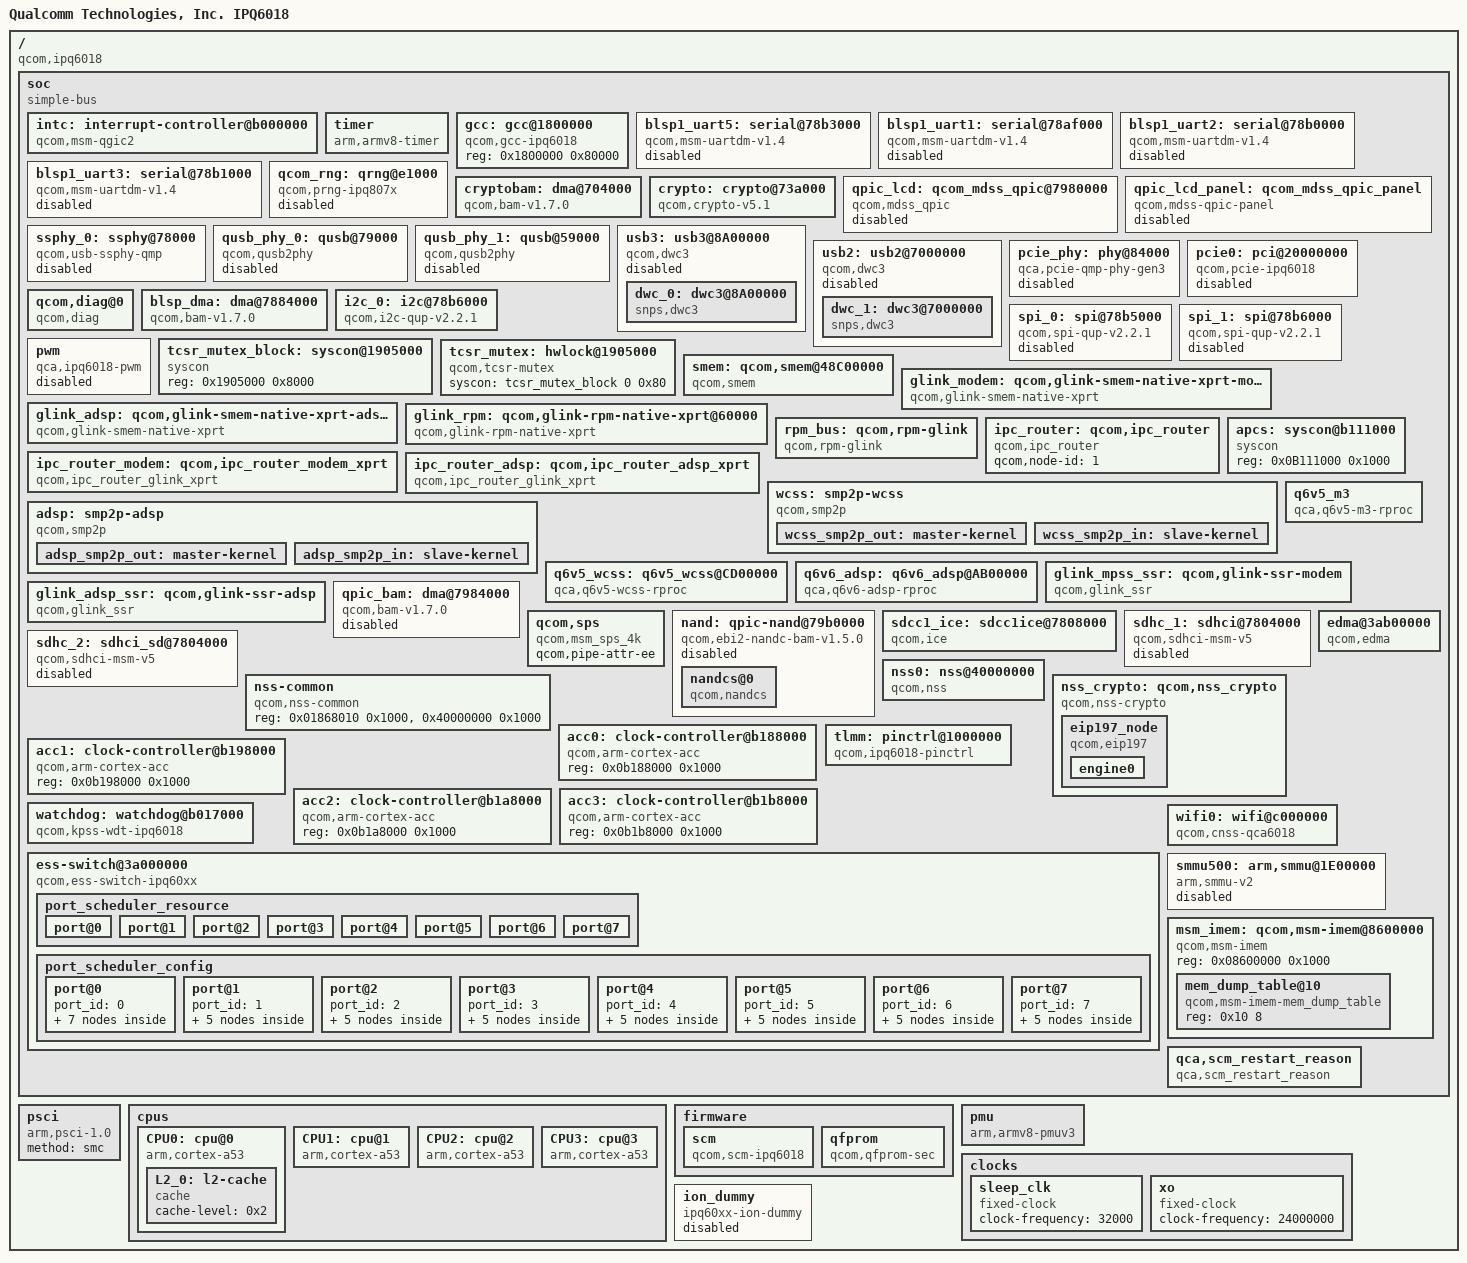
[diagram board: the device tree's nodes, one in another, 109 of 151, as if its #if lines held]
/*
 * Copyright (c) 2018-2019, The Linux Foundation. All rights reserved.
 *
 * Permission to use, copy, modify, and/or distribute this software for any
 * purpose with or without fee is hereby granted, provided that the above
 * copyright notice and this permission notice appear in all copies.
 *
 * THE SOFTWARE IS PROVIDED "AS IS" AND THE AUTHOR DISCLAIMS ALL WARRANTIES
 * WITH REGARD TO THIS SOFTWARE INCLUDING ALL IMPLIED WARRANTIES OF
 * MERCHANTABILITY AND FITNESS. IN NO EVENT SHALL THE AUTHOR BE LIABLE FOR
 * ANY SPECIAL, DIRECT, INDIRECT, OR CONSEQUENTIAL DAMAGES OR ANY DAMAGES
 * WHATSOEVER RESULTING FROM LOSS OF USE, DATA OR PROFITS, WHETHER IN AN
 * ACTION OF CONTRACT, NEGLIGENCE OR OTHER TORTIOUS ACTION, ARISING OUT OF
 * OR IN CONNECTION WITH THE USE OR PERFORMANCE OF THIS SOFTWARE.
 */

#include <dt-bindings/interrupt-controller/arm-gic.h>
#include <dt-bindings/clock/qcom,gcc-ipq6018.h>
#include "qcom-ipq6018-memory.dtsi"

/ {
	model = "Qualcomm Technologies, Inc. IPQ6018";
	compatible = "qcom,ipq6018";
	qcom,msm-id = <0x192 0x0>;

	soc: soc {
		#address-cells = <0x1>;
		#size-cells = <0x1>;
		ranges = <0 0 0 0xffffffff>;
		compatible = "simple-bus";

		intc: interrupt-controller@b000000 {
			compatible = "qcom,msm-qgic2";
			interrupt-controller;
			#interrupt-cells = <0x3>;
			reg = <0xb000000 0x1000>, <0xb002000 0x1000>;
		};

		timer {
			compatible = "arm,armv8-timer";
			interrupts = <GIC_PPI 2 (GIC_CPU_MASK_SIMPLE(4) | IRQ_TYPE_LEVEL_LOW)>,
				     <GIC_PPI 3 (GIC_CPU_MASK_SIMPLE(4) | IRQ_TYPE_LEVEL_LOW)>,
				     <GIC_PPI 4 (GIC_CPU_MASK_SIMPLE(4) | IRQ_TYPE_LEVEL_LOW)>,
				     <GIC_PPI 1 (GIC_CPU_MASK_SIMPLE(4) | IRQ_TYPE_LEVEL_LOW)>;
		};

		gcc: gcc@1800000 {
			compatible = "qcom,gcc-ipq6018";
			reg = <0x1800000 0x80000>;
			#clock-cells = <0x1>;
			#reset-cells = <0x1>;
		};

		blsp1_uart5: serial@78b3000 {
			compatible = "qcom,msm-uartdm-v1.4", "qcom,msm-uartdm";
			reg = <0x78b3000 0x200>;
			interrupts = <GIC_SPI 308 IRQ_TYPE_LEVEL_HIGH>;
			clocks = <&gcc GCC_BLSP1_UART5_APPS_CLK>,
				 <&gcc GCC_BLSP1_AHB_CLK>;
			clock-names = "core", "iface";
			status = "disabled";
		};

		blsp1_uart1: serial@78af000 {
			compatible = "qcom,msm-uartdm-v1.4", "qcom,msm-uartdm";
			reg = <0x78af000 0x200>;
			interrupts = <GIC_SPI 107 IRQ_TYPE_LEVEL_HIGH>;
			clocks = <&gcc GCC_BLSP1_UART1_APPS_CLK>,
				 <&gcc GCC_BLSP1_AHB_CLK>;
			clock-names = "core", "iface";
			status = "disabled";
		};

		blsp1_uart2: serial@78b0000 {
			compatible = "qcom,msm-uartdm-v1.4", "qcom,msm-uartdm";
			reg = <0x78b0000 0x200>;
			interrupts = <GIC_SPI 108 IRQ_TYPE_LEVEL_HIGH>;
			clocks = <&gcc GCC_BLSP1_UART2_APPS_CLK>,
				<&gcc GCC_BLSP1_AHB_CLK>;
			clock-names = "core", "iface";
			status = "disabled";
		};

		blsp1_uart3: serial@78b1000 {
			compatible = "qcom,msm-uartdm-v1.4", "qcom,msm-uartdm";
			reg = <0x78b1000 0x200>;
			interrupts = <GIC_SPI 306 IRQ_TYPE_LEVEL_HIGH>;
			clocks = <&gcc GCC_BLSP1_UART3_APPS_CLK>,
				<&gcc GCC_BLSP1_AHB_CLK>;
			clock-names = "core", "iface";
			status = "disabled";
		};

		qcom_rng: qrng@e1000 {
			compatible = "qcom,prng-ipq807x";
			reg = <0xe3000 0x1000>;
			clocks = <&gcc GCC_PRNG_AHB_CLK>;
			clock-names = "core";
			status = "disabled";
		};

		cryptobam: dma@704000 {
			compatible = "qcom,bam-v1.7.0";
			reg = <0x00704000 0x20000>;
			interrupts = <GIC_SPI 207 IRQ_TYPE_NONE>;
			clocks = <&gcc GCC_CRYPTO_AHB_CLK>;
			clock-names = "bam_clk";
			#dma-cells = <1>;
			qcom,ee = <1>;
			qcom,controlled-remotely = <1>;
			qcom,config-pipe-trust-reg = <0>;
		};

		crypto: crypto@73a000 {
			compatible = "qcom,crypto-v5.1";
			reg = <0x0073a000 0x6000>;
			clocks = <&gcc GCC_CRYPTO_AHB_CLK>,
				<&gcc GCC_CRYPTO_AXI_CLK>,
				<&gcc GCC_CRYPTO_CLK>;
			clock-names = "iface", "bus", "core";
			dmas = <&cryptobam 2>, <&cryptobam 3>;
			dma-names = "rx", "tx";
		};

		qpic_lcd: qcom_mdss_qpic@7980000 {
			compatible = "qcom,mdss_qpic";
			reg = <0x7980000 0x24000>;
			interrupts = <GIC_SPI 151 IRQ_TYPE_NONE>;
			clocks = <&gcc GCC_QPIC_CLK>,
				<&gcc GCC_QPIC_AHB_CLK>;
			clock-names = "core", "aon";
			dmas = <&qpic_bam 6>;
			dma-names = "chan";
			status = "disabled";
		};

		qpic_lcd_panel: qcom_mdss_qpic_panel {
			compatible = "qcom,mdss-qpic-panel";
			label = "qpic lcd panel";
			qcom,mdss-pan-res = <800 480>;
			qcom,mdss-pan-bpp = <18>;
			qcom,refresh_rate = <60>;
			status = "disabled";
		};

		ssphy_0: ssphy@78000 {
			compatible = "qcom,usb-ssphy-qmp";
			reg = <0x78000 0x45c>,
				<0x0193f244 0x4>,
				<0x08af8800 0x100>,
				<0x7e000 0x18>;
			reg-names = "qmp_phy_base",
				    "vls_clamp_reg",
				    "qscratch_base",
				    "ahb2phy_base";
			qcom,qmp-phy-init-seq = <0xac 0x14 0x1a 0x00
						0x34 0x08 0x08 0x00
						0x174 0x30 0x30 0x00
						0x3c 0x06 0x06 0x00
						0xb4 0x00 0x00 0x00
						0xb8 0x08 0x08 0x00
						0x194 0x06 0x06 0x3e8
						0x19c 0x01 0x01 0x00
						0x178 0x00 0x00 0x00
						0xd0 0x68 0x68 0x00
						0xdc 0xab 0xab 0x00
						0xe0 0xaa 0xaa 0x00
						0xe4 0x02 0x02 0x00
						0x78 0x09 0x09 0x00
						0x84 0x16 0x16 0x00
						0x90 0x28 0x28 0x00
						0x108 0xa0 0xa0 0x00
						0x10c 0x00 0x00 0x00
						0x184 0x0a 0x0a 0x00
						0x4c 0xaa 0xaa 0x00
						0x50 0x29 0x29 0x00
						0x54 0x00 0x00 0x00
						0xc8 0x00 0x00 0x00
						0x18c 0x00 0x00 0x00
						0xcc 0x00 0x00 0x00
						0x128 0x00 0x00 0x00
						0x0c 0x0a 0x0a 0x00
						0x10 0x01 0x01 0x00
						0x1c 0x7d 0x7d 0x00
						0x20 0x01 0x01 0x00
						0x14 0x00 0x00 0x00
						0x18 0x00 0x00 0x00
						0x24 0x0a 0x0a 0x00
						0x28 0x05 0x05 0x00
						0x48 0x0f 0x0f 0x00
						0x70 0x0f 0x0f 0x00
						0x100 0x80 0x80 0x00
						0x440 0x0b 0x0b 0x00
						0x4d8 0x02 0x02 0x00
						0x4dc 0x6c 0x6c 0x00
						0x4e0 0xbb 0xb8 0x00
						0x508 0x77 0x77 0x00
						0x50c 0x80 0x80 0x00
						0x514 0x03 0x03 0x00
						0x51c 0x16 0x16 0x00
						0x448 0x75 0x75 0x00
						0x454 0x00 0x00 0x00
						0x40c 0x0a 0x0a 0x00
						0x41c 0x06 0x06 0x00
						0x510 0x00 0x00 0x00
						0x268 0x45 0x45 0x00
						0x2ac 0x12 0x12 0x00
						0x294 0x06 0x06 0x00
						0x254 0x00 0x00 0x00
						0x8c8 0x83 0x83 0x00
						0x8c4 0x02 0x02 0x00
						0x8cc 0x09 0x09 0x00
						0x8d0 0xa2 0xa2 0x00
						0x8d4 0x85 0x85 0x00
						0x880 0xd1 0xd1 0x00
						0x884 0x1f 0x1f 0x00
						0x888 0x47 0x47 0x00
						0x80c 0x9f 0x9f 0x00
						0x824 0x17 0x17 0x00
						0x828 0x0f 0x0f 0x00
						0x8b8 0x75 0x75 0x00
						0x8bc 0x13 0x13 0x00
						0x8b0 0x86 0x86 0x00
						0x8a0 0x04 0x04 0x00
						0x88c 0x44 0x44 0x00
						0x870 0xe7 0xe7 0x00
						0x874 0x03 0x03 0x00
						0x878 0x40 0x40 0x00
						0x87c 0x00 0x00 0x00
						0x9d8 0x88 0x88 0x00
						0xffffffff 0xffffffff 0x00 0x00>;
			qcom,qmp-phy-reg-offset = <0x988 0x98c 0x990 0x994
						0x974 0x8d8 0x8dc 0x804 0x800
						0x808>;

			clocks = <&gcc GCC_USB0_AUX_CLK>,
				 <&gcc GCC_USB0_PIPE_CLK>;

			clock-names = "aux_clk", "pipe_clk";

			resets =  <&gcc GCC_USB0_PHY_BCR>,
				  <&gcc GCC_USB3PHY_0_PHY_BCR>;
			reset-names = "usb3_phy_reset",
				      "usb3phy_phy_reset";

			status = "disabled";
		 };

		qusb_phy_0: qusb@79000 {
			compatible = "qcom,qusb2phy";
			reg = <0x079000 0x180>,
			      <0x08af8800 0x400>,
			      <0x01841030 0x4>,
			      <0x08A0C12C 0x4>;
			reg-names = "qusb_phy_base",
				    "qscratch_base",
				    "ref_clk_addr",
				    "usb3_guctl_addr";

			qcom,qusb-phy-init-seq = <0x14 0x00
						  0xF8 0x80
						  0xB3 0x84
						  0x83 0x88
						  0xC0 0x8C
						  0x30 0x08
						  0x79 0x0C
						  0x21 0x10
						  0x00 0x90
						  0x00 0x18
						  0x14 0x9C
						  0x80 0x04
						  0x9F 0x1C>;
			phy_type= "utmi";

			resets = <&gcc GCC_QUSB2_0_PHY_BCR>;
			reset-names = "usb2_phy_reset";

			status = "disabled";
		};

		qusb_phy_1: qusb@59000 {
			compatible = "qcom,qusb2phy";
			reg = <0x059000 0x180>,
			      <0x070f8800 0x400>,
			      <0x01841030 0x4>,
			      <0x0700C12C 0x4>;
			reg-names = "qusb_phy_base",
				    "qscratch_base",
				    "ref_clk_addr",
				    "usb3_guctl_addr";
			qcom,qusb-phy-init-seq = <0x14 0x00
						  0xF8 0x80
						  0xB3 0x84
						  0x83 0x88
						  0xC0 0x8C
						  0x30 0x08
						  0x79 0x0C
						  0x21 0x10
						  0x00 0x90
						  0x00 0x18
						  0x14 0x9C
						  0x80 0x04
						  0x9F 0x1C>;

			phy_type= "utmi";

			resets = <&gcc GCC_QUSB2_1_PHY_BCR>;
			reset-names = "usb2_phy_reset";

			status = "disabled";
		};

		usb3: usb3@8A00000 {
			compatible = "qcom,dwc3";
			#address-cells = <1>;
			#size-cells = <1>;
			ranges;
			reg = <0x8AF8800 0x100>;
			reg-names = "qscratch_base";
			clocks = <&gcc GCC_SNOC_BUS_TIMEOUT2_AHB_CLK>,
			         <&gcc GCC_SYS_NOC_USB0_AXI_CLK>,
			         <&gcc GCC_USB0_MASTER_CLK>,
			         <&gcc GCC_USB0_SLEEP_CLK>,
			         <&gcc GCC_USB0_MOCK_UTMI_CLK>,
			         <&gcc GCC_USB0_PHY_CFG_AHB_CLK>,
			         <&gcc GCC_USB0_AUX_CLK>,
			         <&gcc GCC_USB0_PIPE_CLK>;
			clock-names = "snoc_bus_timeout2",
				      "sys_noc_axi",
				      "master",
				      "sleep",
				      "mock_utmi",
				      "cfg_ahb_clk",
				      "aux_clk",
				      "pipe_clk";
			assigned-clocks = <&gcc GCC_SYS_NOC_USB0_AXI_CLK>,
					  <&gcc GCC_USB0_MASTER_CLK>,
					  <&gcc GCC_USB0_MOCK_UTMI_CLK>;
			assigned-clock-rates = <133330000>,
						<133330000>,
						<20000000>;
			qca,host = <1>;
			status = "disabled";

			dwc_0: dwc3@8A00000 {
			       compatible = "snps,dwc3";
			       reg = <0x8A00000 0xcd00>;
			       interrupts = <GIC_SPI 140 IRQ_TYPE_NONE>;
			       usb-phy = <&qusb_phy_0>, <&ssphy_0>;
			       tx-fifo-resize;
			       snps,usb3-u1u2-disable;
			       snps,nominal-elastic-buffer;
			       snps,is-utmi-l1-suspend;
			       snps,hird-threshold = /bits/ 8 <0x0>;
			       snps,dis_u2_susphy_quirk;
			       snps,dis_u3_susphy_quirk;
			       usb2-susphy-quirk;
			       qcom,emulation = <1>;
			       dr_mode = "host";
			};
		};

		usb2: usb2@7000000 {
			compatible = "qcom,dwc3";
			#address-cells = <1>;
			#size-cells = <1>;
			ranges;
			reg = <0x70F8800 0x100>;
			reg-names = "qscratch_base";
			clocks = <&gcc GCC_USB1_MASTER_CLK>,
			         <&gcc GCC_USB1_SLEEP_CLK>,
			         <&gcc GCC_USB1_MOCK_UTMI_CLK>,
			         <&gcc GCC_USB1_PHY_CFG_AHB_CLK>;
			clock-names = "master",
				      "sleep",
				      "mock_utmi",
				      "cfg_ahb_clk";

			assigned-clocks = <&gcc GCC_USB1_MASTER_CLK>,
					  <&gcc GCC_USB1_MOCK_UTMI_CLK>;
			assigned-clock-rates = <133330000>,
					       <20000000>;
			qca,host = <1>;
			status = "disabled";

			dwc_1: dwc3@7000000 {
			       compatible = "snps,dwc3";
			       reg = <0x7000000 0xcd00>;
			       interrupts = <GIC_SPI 99 IRQ_TYPE_NONE>;
			       usb-phy = <&qusb_phy_1>;
			       tx-fifo-resize;
			       snps,usb3-u1u2-disable;
			       snps,nominal-elastic-buffer;
			       snps,is-utmi-l1-suspend;
			       snps,hird-threshold = /bits/ 8 <0x0>;
			       snps,dis_u2_susphy_quirk;
			       snps,dis_u3_susphy_quirk;
			       usb2-susphy-quirk;
			       qcom,emulation = <1>;
			       dr_mode = "host";
			};
		};

		pcie_phy: phy@84000 {
			compatible = "qca,pcie-qmp-phy-gen3";
			reg = <0x84000 0x1000>;
			qcom,qmp-pcie-phy-init-seq = <0x840 0x01 /*PCS_COM_POWER_DOWN_CONTROL */
						      0x03C 0x18 /* PCIE_0_QSERDES_PLL_BIAS_EN_CLKBUFLR_EN */
						      0x0A4 0x01 /* PCIE_0_QSERDES_PLL_BIAS_EN_CTRL_BY_PSM */
						      0x16C 0x31 /* PCIE_0_QSERDES_PLL_CLK_SELECT */
						      0x050 0x0F /* PCIE_0_QSERDES_PLL_PLL_IVCO */
						      0x074 0x0F /* PCIE_0_QSERDES_PLL_BG_TRIM */
						      0xFFFFFFFF 0x01 /* 1ms delay */
						      0x18C 0x06 /* PCIE_0_QSERDES_PLL_CMN_CONFIG */
						      0x0C4 0x42 /* PCIE_0_QSERDES_PLL_LOCK_CMP_EN */
						      0x0B0 0x20 /* PCIE_0_QSERDES_PLL_RESETSM_CNTRL */
						      0x194 0x01 /* PCIE_0_QSERDES_PLL_SVS_MODE_CLK_SEL */
						      0x120 0x04 /* PCIE_0_QSERDES_PLL_VCO_TUNE_MAP */
						      0x194 0x05 /* PCIE_0_QSERDES_PLL_SVS_MODE_CLK_SEL */
						      0x13C 0xFF /* PCIE_0_QSERDES_PLL_VCO_TUNE_TIMER1 */
						      0x140 0x3F /* PCIE_0_QSERDES_PLL_VCO_TUNE_TIMER2 */
						      0x184 0x30 /* PCIE_0_QSERDES_PLL_CORE_CLK_EN */
						      0x170 0x21 /* PCIE_0_QSERDES_PLL_HSCLK_SEL */
						      0x0CC 0x68 /* PCIE_0_QSERDES_PLL_DEC_START_MODE0 */
						      0x0E0 0x02 /* PCIE_0_QSERDES_PLL_DIV_FRAC_START3_MODE0 */
						      0x0DC 0xAA /* PCIE_0_QSERDES_PLL_DIV_FRAC_START2_MODE0 */
						      0x0D8 0xAB /* PCIE_0_QSERDES_PLL_DIV_FRAC_START1_MODE0 */
						      0x058 0x29 /* PCIE_0_QSERDES_PLL_LOCK_CMP2_MODE0 */
						      0x054 0xAA /* PCIE_0_QSERDES_PLL_LOCK_CMP1_MODE0 */
						      0x01C 0x7D /* PCIE_0_QSERDES_PLL_CP_CTRL_MODE0 */
						      0x020 0x01 /* PCIE_0_QSERDES_PLL_SSC_PER1 */
						      0x024 0x0A /* PCIE_0_QSERDES_PLL_SSC_PER2 */
						      0x028 0x05 /* PCIE_0_QSERDES_PLL_SSC_STEP_SIZE1_MODE0 */
						      0x080 0x09 /* PCIE_0_QSERDES_PLL_SSC_STEP_SIZE2_MODE0 */
						      0x088 0x16 /* PCIE_0_QSERDES_PLL_PLL_RCTRL_MODE0 */
						      0x090 0x28 /* PCIE_0_QSERDES_PLL_PLL_CCTRL_MODE0 */
						      0x104 0x00 /* PCIE_0_QSERDES_PLL_INTEGLOOP_GAIN1_MODE0 */
						      0x100 0xA0 /* PCIE_0_QSERDES_PLL_INTEGLOOP_GAIN0_MODE0 */
						      0x128 0x02 /* PCIE_0_QSERDES_PLL_VCO_TUNE2_MODE0 */
						      0x124 0x24 /* PCIE_0_QSERDES_PLL_VCO_TUNE1_MODE0 */
						      0x194 0x05 /* PCIE_0_QSERDES_PLL_SVS_MODE_CLK_SEL */
						      0x184 0x20 /* PCIE_0_QSERDES_PLL_CORE_CLK_EN */
						      0x17C 0x0A /* PCIE_0_QSERDES_PLL_CORECLK_DIV */
						      0x16C 0x32 /* PCIE_0_QSERDES_PLL_CLK_SELECT */
						      0x044 0x02 /* PCIE_0_QSERDES_PLL_SYS_CLK_CTRL */
						      0x048 0x07 /* PCIE_0_QSERDES_PLL_SYSCLK_BUF_ENABLE */
						      0x0A8 0x08 /* PCIE_0_QSERDES_PLL_SYSCLK_EN_SEL */
						      0x00C 0x0A /* PCIE_0_QSERDES_PLL_BG_TIMER */
						      0x170 0x01 /* PCIE_0_QSERDES_PLL_HSCLK_SEL */
						      0x0D0 0x68 /* PCIE_0_QSERDES_PLL_DEC_START_MODE1 */
						      0x0EC 0x02 /* PCIE_0_QSERDES_PLL_DIV_FRAC_START3_MODE1 */
						      0x0E8 0x2AA /* PCIE_0_QSERDES_PLL_DIV_FRAC_START2_MODE1 */
						      0x0E4 0x2AAAB /* PCIE_0_QSERDES_PLL_DIV_FRAC_START2_MODE1 */
						      0x064 0x34 /* PCIE_0_QSERDES_PLL_LOCK_CMP2_MODE1 */
						      0X060 0x3414 /* PCIE_0_QSERDES_PLL_LOCK_CMP1_MODE1 */
						      0x084 0x0B /* PCIE_0_QSERDES_PLL_CP_CTRL_MODE1 */
						      0x08C 0x16 /* PCIE_0_QSERDES_PLL_PLL_RCTRL_MODE1 */
						      0x094 0x28 /* PCIE_0_QSERDES_PLL_PLL_CCTRL_MODE1 */
						      0x10C 0x00 /* PCIE_0_QSERDES_PLL_INTEGLOOP_GAIN1_MODE1 */
						      0x108 0x40 /* PCIE_0_QSERDES_PLL_INTEGLOOP_GAIN0_MODE1 */
						      0x130 0x03 /* PCIE_0_QSERDES_PLL_VCO_TUNE2_MODE1 */
						      0x12C 0xB4 /* PCIE_0_QSERDES_PLL_VCO_TUNE1_MODE1 */
						      0x194 0x05 /* PCIE_0_QSERDES_PLL_SVS_MODE_CLK_SEL */
						      0x184 0x00 /* PCIE_0_QSERDES_PLL_CORE_CLK_EN */
						      0x1B4 0x08 /* PCIE_0_QSERDES_PLL_CORECLK_DIV_MODE1 */
						      0x23C 0x02 /* PCIE_0_QSERDES_TX0_RES_CODE_LANE_OFFSET_TX */
						      0x29C 0x12 /* PCIE_0_QSERDES_TX0_RCV_DETECT_LVL_2 */
						      0x258 0x10 /* PCIE_0_QSERDES_TX0_HIGHZ_DRVR_EN */
						      0x284 0x06 /* PCIE_0_QSERDES_TX0_LANE_MODE_1 */
						      0x51C 0x03 /* PCIE_0_QSERDES_RX0_SIGDET_CNTRL */
						      0x518 0x1C /* PCIE_0_QSERDES_RX0_SIGDET_ENABLES */
						      0x524 0x14 /* PCIE_0_QSERDES_RX0_SIGDET_DEGLITCH_CNTRL */
						      0x4EC 0x0E /* PCIE_0_QSERDES_RX0_RX_EQU_ADAPTOR_CNTRL2 */
						      0x4F0 0x04 /* PCIE_0_QSERDES_RX0_RX_EQU_ADAPTOR_CNTRL3 */
						      0x4F4 0x1B /* PCIE_0_QSERDES_RX0_RX_EQU_ADAPTOR_CNTRL4 */
						      0x5B4 0x04 /* PCIE_0_QSERDES_RX0_DFE_EN_TIMER */
						      0x434 0x7F /* PCIE_0_QSERDES_RX0_UCDR_SO_SATURATION_AND_ENABLE */
						      0x444 0x70 /* PCIE_0_QSERDES_RX0_UCDR_PI_CONTROLS */
						      0x510 0x73 /* PCIE_0_QSERDES_RX0_RX_EQ_OFFSET_ADAPTOR_CNTRL1 */
						      0x514 0x80 /* PCIE_0_QSERDES_RX0_RX_OFFSET_ADAPTOR_CNTRL2 */
						      0x598 0x00 /* PCIE_0_QSERDES_RX0_RX_MODE_10_LOW */
						      0x59C 0x02 /* PCIE_0_QSERDES_RX0_RX_MODE_10_HIGH */
						      0x5A0 0xC8 /* PCIE_0_QSERDES_RX0_RX_MODE_10_HIGH2 */
						      0x5A4 0x09 /* PCIE_0_QSERDES_RX0_RX_MODE_10_HIGH3 */
						      0x5A8 0xB1 /* PCIE_0_QSERDES_RX0_RX_MODE_10_HIGH4 */
						      0x584 0x00 /* PCIE_0_QSERDES_RX0_RX_MODE_01_LOW */
						      0x588 0x02 /* PCIE_0_QSERDES_RX0_RX_MODE_01_HIGH */
						      0x58C 0xC8 /* PCIE_0_QSERDES_RX0_RX_MODE_01_HIGH2 */
						      0x590 0x09 /* PCIE_0_QSERDES_RX0_RX_MODE_01_HIGH3 */
						      0x594 0xB1 /* PCIE_0_QSERDES_RX0_RX_MODE_01_HIGH4 */
						      0x570 0xF0 /* PCIE_0_QSERDES_RX0_RX_MODE_00_LOW */
						      0x574 0x02 /* PCIE_0_QSERDES_RX0_RX_MODE_00_HIGH */
						      0x578 0x2F /* PCIE_0_QSERDES_RX0_RX_MODE_00_HIGH2 */
						      0x57C 0xD3 /* PCIE_0_QSERDES_RX0_RX_MODE_00_HIGH3 */
						      0x580 0x40 /* PCIE_0_QSERDES_RX0_RX_MODE_00_HIGH4 */
						      0x4FC 0x00 /* PCIE_0_QSERDES_RX0_RX_IDAC_TSETTLE_HIGH */
						      0x4F8 0xC0 /* PCIE_0_QSERDES_RX0_RX_IDAC_TSETTLE_LOW */
						      0x89C 0x83 /* PCIE_0_PCS_COM_FLL_CNTRL2 */
						      0x8A0 0x09 /* PCIE_0_PCS_COM_FLL_CNT_VAL_L */
						      0x8A4 0xA2 /* PCIE_0_PCS_COM_FLL_CNT_VAL_H_TOL */
						      0x8A8 0x40 /* PCIE_0_PCS_COM_FLL_MAN_CODE */
						      0x898 0x01 /* PCIE_0_PCS_COM_FLL_CNTRL1 */
						      0x9A8 0x00 /* PCIE_0_PCS_COM_P2U3_WAKEUP_DLY_TIME_AUXCLK_H */
						      0x9A4 0x01 /* PCIE_0_PCS_COM_P2U3_WAKEUP_DLY_TIME_AUXCLK_L */
						      0xC90 0x00 /* PCIE_0_PCS_PCIE_OSC_DTCT_ACTIONS */
						      0xC44 0x00 /* PCIE_0_PCS_PCIE_L1P1_WAKEUP_DLY_TIME_AUXCLK_H */
						      0xC40 0x01 /* PCIE_0_PCS_PCIE_L1P1_WAKEUP_DLY_TIME_AUXCLK_L */
						      0xC4C 0x00 /* PCIE_0_PCS_PCIE_L1P2_WAKEUP_DLY_TIME_AUXCLK_H */
						      0xC48 0x01 /* PCIE_0_PCS_PCIE_L1P2_WAKEUP_DLY_TIME_AUXCLK_L */
						      0xCA0 0x11 /* PCIE_0_PCS_PCIE_EQ_CONFIG1 */
						      0xCA4 0x0B /* PCIE_0_PCS_PCIE_EQ_CONFIG2 */
						      0xC14 0x07 /* PCIE_0_PCS_PCIE_POWER_STATE_CONFIG4 */
						      0xC5C 0x52 /* PCIE_0_PCS_PCIE_OSC_DTCT_CONFIG2 */
						      0xC78 0x50 /* PCIE_0_PCS_PCIE_OSC_DTCT_MODE2_CONFIG2 */
						      0xC80 0x1A /* PCIE_0_PCS_PCIE_OSC_DTCT_MODE2_CONFIG4 */
						      0xC84 0x06 /* PCIE_0_PCS_PCIE_OSC_DTCT_MODE2_CONFIG5 */
						      0x078 0x19 /* PCIE_0_QSERDES_PLL_CLK_EP_DIV_MODE0 */
						      0x07C 0x28 /* PCIE_0_QSERDES_PLL_CLK_EP_DIV_MODE1 */
						      0x040 0x90 /* PCIE_0_QSERDES_PLL_CLK_ENABLE1 */
						      0x840 0x03 /* PCIE_0_PCS_COM_POWER_DOWN_CONTROL */
						      0xC1C 0xC1 /* PCIE_0_PCS_PCIE_ENDPOINT_REFCLK_DRIVE */
						      0x9D8 0x01 /* PCIE_0_PCS_COM_RX_DCC_CAL_CONFIG */
						      0x988 0xAA /* PCIE_0_PCS_COM_RX_SIGDET_LVL */
						      0x8DC 0x0D /* PCIE_0_PCS_COM_REFGEN_REQ_CONFIG1 */
						      0x800 0x00 /* PCIE_0_PCS_COM_SW_RESET */
						      0x844 0x03>; /* PCIE_0_PCS_COM_START_CONTROL */

			#phy-cells = <0>;
			clocks = <&gcc GCC_PCIE0_PIPE_CLK>;
			clock-names = "pipe_clk";

			resets = <&gcc GCC_PCIE0_PHY_BCR>,
				<&gcc GCC_PCIE0PHY_PHY_BCR>;
			reset-names = "phy",
				      "phy_phy";
			status = "disabled";
		};


		pcie0: pci@20000000 {
			compatible = "qcom,pcie-ipq6018";
			reg =  <0x20000000 0xf1d
				0x20000F20 0xa8
				0x20001000 0x1000
				0x80000 0x2000
				0x20100000 0x1000>;
			reg-names = "dbi", "elbi", "dm_iatu", "parf", "config";
			device_type = "pci";
			linux,pci-domain = <0>;
			bus-range = <0x00 0xff>;
			num-lanes = <1>;
			#address-cells = <3>;
			#size-cells = <2>;

			phys = <&pcie_phy>;
			phy-names ="pciephy-gen3";

			ranges = <0x81000000 0 0x20200000 0x20200000
				  0 0x00100000   /* downstream I/O */
				  0x82000000 0 0x20300000 0x20300000
				  0 0x10000000>; /* non-prefetchable memory */

			interrupts = <GIC_SPI 52 IRQ_TYPE_NONE>;
			interrupt-names = "msi";
			#interrupt-cells = <1>;
			interrupt-map-mask = <0 0 0 0x7>;
			interrupt-map = <0 0 0 1 &intc 0 75
					 IRQ_TYPE_LEVEL_HIGH>, /* int_a */
					<0 0 0 2 &intc 0 78
					 IRQ_TYPE_LEVEL_HIGH>, /* int_b */
					<0 0 0 3 &intc 0 79
					 IRQ_TYPE_LEVEL_HIGH>, /* int_c */
					<0 0 0 4 &intc 0 83
					 IRQ_TYPE_LEVEL_HIGH>; /* int_d */

			clocks = <&gcc GCC_SYS_NOC_PCIE0_AXI_CLK>,
				 <&gcc GCC_PCIE0_AXI_M_CLK>,
				 <&gcc GCC_PCIE0_AXI_S_CLK>,
				 <&gcc GCC_PCIE0_AHB_CLK>,
				 <&gcc GCC_PCIE0_AUX_CLK>,
				 <&gcc GCC_PCIE0_AXI_S_BRIDGE_CLK>,
				 <&gcc PCIE0_RCHNG_CLK>;

			clock-names = "sys_noc",
				      "axi_m",
				      "axi_s",
				      "ahb",
				      "aux",
				      "axi_bridge",
				      "rchng";
			resets = <&gcc GCC_PCIE0_PIPE_ARES>,
				 <&gcc GCC_PCIE0_SLEEP_ARES>,
				 <&gcc GCC_PCIE0_CORE_STICKY_ARES>,
				 <&gcc GCC_PCIE0_AXI_MASTER_ARES>,
				 <&gcc GCC_PCIE0_AXI_SLAVE_ARES>,
				 <&gcc GCC_PCIE0_AHB_ARES>,
				 <&gcc GCC_PCIE0_AXI_MASTER_STICKY_ARES>,
				 <&gcc GCC_PCIE0_AXI_SLAVE_STICKY_ARES>;
			reset-names = "pipe",
				      "sleep",
				      "sticky",
				      "axi_m",
				      "axi_s",
				      "ahb",
				      "axi_m_sticky",
				      "axi_s_sticky";

			perst-gpio = <&tlmm 60 1>;
			status = "disabled";
		};

		qcom,diag@0 {
			compatible = "qcom,diag";
			status = "ok";
		};

		blsp_dma: dma@7884000 {
			compatible = "qcom,bam-v1.7.0";
			reg = <0x07884000 0x2b000>;
			interrupts = <GIC_SPI 238 IRQ_TYPE_NONE>;
			clocks = <&gcc GCC_BLSP1_AHB_CLK>;
			clock-names = "bam_clk";
			#dma-cells = <1>;
			qcom,ee = <0>;
		};

		i2c_0: i2c@78b6000 {
			compatible = "qcom,i2c-qup-v2.2.1";
			#address-cells = <1>;
			#size-cells = <0>;
			reg = <0x78b6000 0x600>;
			interrupts = <GIC_SPI 96 IRQ_TYPE_LEVEL_HIGH>;
			clocks = <&gcc GCC_BLSP1_AHB_CLK>,
				<&gcc GCC_BLSP1_QUP2_I2C_APPS_CLK>;
			clock-names = "iface", "core";
			clock-frequency  = <400000>;
			dmas = <&blsp_dma 15>, <&blsp_dma 14>;
			dma-names = "rx", "tx";
		};

		spi_0: spi@78b5000 { /* BLSP1 QUP0 */
			compatible = "qcom,spi-qup-v2.2.1";
			#address-cells = <1>;
			#size-cells = <0>;
			reg = <0x78b5000 0x600>;
			interrupts = <GIC_SPI 95 IRQ_TYPE_NONE>;
			spi-max-frequency = <50000000>;
			clocks = <&gcc GCC_BLSP1_QUP1_SPI_APPS_CLK>,
				<&gcc GCC_BLSP1_AHB_CLK>;
			clock-names = "core", "iface";
			dmas = <&blsp_dma 12>, <&blsp_dma 13>;
			dma-names = "tx", "rx";
			status = "disabled";
		};

		spi_1: spi@78b6000 {
			compatible = "qcom,spi-qup-v2.2.1";
			#address-cells = <1>;
			#size-cells = <0>;
			reg = <0x78b6000 0x600>;
			interrupts = <0 96 0>;
			spi-max-frequency = <50000000>;
			clocks = <&gcc GCC_BLSP1_QUP2_SPI_APPS_CLK>,
				<&gcc GCC_BLSP1_AHB_CLK>;
			clock-names = "core", "iface";
			dmas = <&blsp_dma 14>, <&blsp_dma 15>;
			dma-names = "tx", "rx";
			status = "disabled";
		};

		pwm {
			compatible = "qca,ipq6018-pwm";
			reg = <0x1941010 0x20>;
			clocks = <&gcc GCC_ADSS_PWM_CLK>;
			clock-names = "core";
			src-freq = <100000000>;
			pwm-base-index = <0>;
			used-pwm-indices = <1>, <1>, <1>, <1>;
			status = "disabled";
		};

		tcsr_mutex_block: syscon@1905000 {
			compatible = "syscon";
			reg = <0x1905000 0x8000>;
		};

		tcsr_mutex: hwlock@1905000 {
			compatible = "qcom,tcsr-mutex";
			syscon = <&tcsr_mutex_block 0 0x80>;
			#hwlock-cells = <1>;
		};

		smem: qcom,smem@48C00000 {
			compatible = "qcom,smem";
			memory-region = <&smem_region>;
			hwlocks = <&tcsr_mutex 0>;
		};

		glink_modem: qcom,glink-smem-native-xprt-modem@48C00000 {
			compatible = "qcom,glink-smem-native-xprt";
			reg = <0x48C00000 0x100000>, <0x0b111008 0x4>;
			reg-names = "smem", "irq-reg-base";
			qcom,irq-mask = <0x100>;
			interrupts = <GIC_SPI 321 IRQ_TYPE_EDGE_RISING>;
			label = "mpss";
			qcom,subsys-id = <1>;
			smem-entry = <478>, <479>, <480>;
			smem-entry-names = "ch", "tx_fifo", "rx_fifo";
		};

		glink_adsp: qcom,glink-smem-native-xprt-adsp@48C00000 {
			compatible = "qcom,glink-smem-native-xprt";
			reg = <0x48C00000 0x100000>, <0x0b111008 0x4>;
			reg-names = "smem", "irq-reg-base";
			qcom,irq-mask = <0x800000>;
			interrupts = <0 24 1>;
			label = "lpass";
			qcom,subsys-id = <2>;
			smem-entry = <478>, <479>, <480>;
			smem-entry-names = "ch", "tx_fifo", "rx_fifo";
		};

		glink_rpm: qcom,glink-rpm-native-xprt@60000 {
			compatible = "qcom,glink-rpm-native-xprt";
			reg = <0x60000 0x6000>, <0x0b111008 0x4>;
			reg-names = "msgram", "irq-reg-base";
			qcom,irq-mask = <0x1>;
			interrupts = <GIC_SPI 168 IRQ_TYPE_EDGE_RISING>;
			label = "rpm";
			qcom,subsys-id = <6>;
			status = "ok";
		};

		rpm_bus: qcom,rpm-glink {
			compatible = "qcom,rpm-glink";
			qcom,glink-edge = "rpm";
			rpm-channel-name = "rpm_requests";
			qcom,rpm-channel-type = <15>; //SMD_APPS_RPM
			status = "ok";
		};

		ipc_router: qcom,ipc_router {
			compatible = "qcom,ipc_router";
			qcom,node-id = <1>;
		};

		ipc_router_modem: qcom,ipc_router_modem_xprt {
			compatible = "qcom,ipc_router_glink_xprt";
			qcom,ch-name = "IPCRTR";
			qcom,xprt-remote = "mpss";
			qcom,glink-xprt = "smem";
			qcom,xprt-linkid = <1>;
			qcom,xprt-version = <1>;
			qcom,fragmented-data;
		};

		ipc_router_adsp: qcom,ipc_router_adsp_xprt {
			compatible = "qcom,ipc_router_glink_xprt";
			qcom,ch-name = "IPCRTR";
			qcom,xprt-remote = "lpass";
			qcom,glink-xprt = "smem";
			qcom,xprt-linkid = <1>;
			qcom,xprt-version = <1>;
			qcom,fragmented-data;
		};

		apcs: syscon@b111000 {
			compatible = "syscon";
			reg = <0x0B111000 0x1000>;
		};

		wcss: smp2p-wcss {
			compatible = "qcom,smp2p";
			qcom,smem = <435>, <428>;

			interrupt-parent = <&intc>;
			interrupts = <GIC_SPI 322 IRQ_TYPE_EDGE_RISING>;

			qcom,ipc = <&apcs 8 9>;

			qcom,local-pid = <0>;
			qcom,remote-pid = <1>;

			wcss_smp2p_out: master-kernel {
				qcom,entry-name = "master-kernel";
				qcom,smp2p-feature-ssr-ack;
				#qcom,smem-state-cells = <1>;
			};

			wcss_smp2p_in: slave-kernel {
				qcom,entry-name = "slave-kernel";

				interrupt-controller;
				#interrupt-cells = <2>;
			};
		};

		adsp: smp2p-adsp {
			compatible = "qcom,smp2p";
			qcom,smem = <443>, <429>;

			interrupt-parent = <&intc>;
			interrupts = <0 26 1>;

			qcom,ipc = <&apcs 8 21>;

			qcom,local-pid = <0>;
			qcom,remote-pid = <2>;

			adsp_smp2p_out: master-kernel {
				qcom,entry-name = "master-kernel";
				qcom,smp2p-feature-ssr-ack;
				#qcom,smem-state-cells = <1>;
			};

			adsp_smp2p_in: slave-kernel {
				qcom,entry-name = "slave-kernel";

				interrupt-controller;
				#interrupt-cells = <2>;
			};
		};

		q6v5_wcss: q6v5_wcss@CD00000 {
			compatible = "qca,q6v5-wcss-rproc";
			firmware = "IPQ6018/q6_fw.mdt";
			reg = <0xCD00000 0x4040>,
				<0x194f000 0x10>,
				<0x1952000 0x10>,
				<0x4ab000 0x20>,
				<0x1818000 0x110>,
				<0x1859000 0x10>,
				<0x1945000 0x10>;
			reg-names = "wcss-base",
					"tcsr-q6-base",
					"tcsr-base",
					"mpm-base",
					"gcc-wcss-bcr-base",
					"gcc-wcss-misc-base",
					"tcsr-global";
			qca,auto-restart;
			qca,extended-intc;
			interrupts-extended = <&intc 0 325 1>,
				<&wcss_smp2p_in 0 0>,
				<&wcss_smp2p_in 1 0>,
				<&wcss_smp2p_in 3 0>;
			interrupt-names = "wdog",
				  "qcom,gpio-err-fatal",
				  "qcom,gpio-err-ready",
				  "qcom,gpio-stop-ack";
			qcom,smem-states = <&wcss_smp2p_out 0>,
				   <&wcss_smp2p_out 1>;
			qcom,smem-state-names = "shutdown",
					"stop";
		};

		q6v5_m3: q6v5_m3 {
			compatible = "qca,q6v5-m3-rproc";
			firmware = "IPQ6018/m3_fw.mdt";
			qca,auto-restart;
			qcom,restart-group = <&q6v5_m3 &q6v5_wcss>;
		};

		q6v6_adsp: q6v6_adsp@AB00000 {
			compatible = "qca,q6v6-adsp-rproc";
			firmware = "IPQ6018/adsp.mdt";
			reg = <0xAB00000 0x4040>,
				<0x181F000 0x4>,
				<0xA000000 0x48000>,
				<0x1954010 0x20>;
			reg-names = "adsp-base",
					"gcc-adsp-bcr-base",
					"adsp-cc-base",
					"tcsr-base";
			qca,auto-restart;
			qca,extended-intc;
			interrupts-extended = <&intc 0 30 1>,
				<&adsp_smp2p_in 0 0>,
				<&adsp_smp2p_in 1 0>,
				<&adsp_smp2p_in 3 0>;
			interrupt-names = "wdog",
				  "qcom,gpio-err-fatal",
				  "qcom,gpio-err-ready",
				  "qcom,gpio-stop-ack";
			qcom,smem-states = <&adsp_smp2p_out 0>,
				   <&adsp_smp2p_out 1>;
			qcom,smem-state-names = "shutdown",
					"stop";
		};

		glink_mpss_ssr: qcom,glink-ssr-modem {
			compatible = "qcom,glink_ssr";
			label = "q6v5-wcss";
			qcom,edge = "mpss";
			qca,no-notify-edges;
			qcom,xprt = "smem";
		};

		glink_adsp_ssr: qcom,glink-ssr-adsp {
			compatible = "qcom,glink_ssr";
			label = "q6v6-adsp";
			qcom,edge = "lpass";
			qca,no-notify-edges;
			qcom,xprt = "smem";
		};

		qpic_bam: dma@7984000{
			compatible = "qcom,bam-v1.7.0";
			reg = <0x7984000 0x1a000>;
			interrupts = <GIC_SPI 146 IRQ_TYPE_NONE>;
			clocks = <&gcc GCC_QPIC_AHB_CLK>;
			clock-names = "bam_clk";
			#dma-cells = <1>;
			qcom,ee = <0>;
			status = "disbaled";
		};

		qcom,sps {
			compatible = "qcom,msm_sps_4k";
			qcom,pipe-attr-ee;
		};

		nand: qpic-nand@79b0000 {
			compatible = "qcom,ebi2-nandc-bam-v1.5.0";
			reg = <0x79b0000 0x10000>;
			#address-cells = <1>;
			#size-cells = <0>;
			clocks = <&gcc GCC_QPIC_CLK>,
				<&gcc GCC_QPIC_AHB_CLK>;
			clock-names = "core", "aon";

			dmas = <&qpic_bam 0>,
				<&qpic_bam 1>,
				<&qpic_bam 2>;
			dma-names = "tx", "rx", "cmd";
			status = "disabled";

			nandcs@0 {
				compatible = "qcom,nandcs";
				reg = <0>;
				#address-cells = <1>;
				#size-cells = <1>;

				nand-ecc-strength = <4>;
				nand-ecc-step-size = <512>;
				nand-bus-width = <8>;
			};
		};

		sdcc1_ice: sdcc1ice@7808000 {
			compatible = "qcom,ice";
			reg = <0x7808000 0x2000>;
			interrupts = <GIC_SPI 312 IRQ_TYPE_NONE>;
			qcom,msm-bus,vectors-KBps =
				<78 512 0 0>,    /* No vote */
				<78 512 1000 0>; /* Max. bandwidth */
			qcom,bus-vector-names = "MIN", "MAX";
			qcom,instance-type = "sdcc";
		};

		sdhc_1: sdhci@7804000 {
			compatible = "qcom,sdhci-msm-v5";
			reg = <0x7804000 0x1000>, <0x7805000 0x1000>;
			reg-names = "hc_mem", "cmdq_mem";

			interrupts = <GIC_SPI 123 IRQ_TYPE_NONE>,
					<GIC_SPI 138 IRQ_TYPE_NONE>;
			interrupt-names = "hc_irq", "pwr_irq";

			qcom,bus-width = <8>;
			sdhc-msm-crypto = <&sdcc1_ice>;

			qcom,dedicated-io = <1>;

			/* device core power supply */
			qcom,vdd-voltage-level = <2900000 2900000>;
			qcom,vdd-current-level = <200 570000>;

			/* device communication power supply */
			qcom,vdd-io-lpm-sup;
			qcom,vdd-io-voltage-level = <1800000 1800000>;
			qcom,vdd-io-current-level = <200 325000>;
			qcom,vdd-io-always-on;

			qcom,cpu-dma-latency-us = <701>;
			qcom,msm-bus,name = "sdhc1";
			qcom,msm-bus,num-cases = <9>;
			qcom,msm-bus,num-paths = <1>;
			qcom,msm-bus,vectors-KBps = <78 512 0 0>, /* No vote */
				<78 512 1046 3200>,    /* 400 KB/s*/
				<78 512 52286 160000>, /* 20 MB/s */
				<78 512 65360 200000>, /* 25 MB/s */
				<78 512 130718 400000>, /* 50 MB/s */
				<78 512 261438 800000>, /* 100 MB/s */
				<78 512 261438 800000>, /* 200 MB/s */
				<78 512 261438 800000>, /* 400 MB/s */
				<78 512 1338562 4096000>; /* Max. bandwidth */
			qcom,bus-bw-vectors-bps = <0 400000 20000000 25000000 \
						50000000 100000000 200000000 \
						400000000 4294967295>;

			clocks = <&gcc GCC_SDCC1_AHB_CLK>,
				 <&gcc GCC_SDCC1_APPS_CLK>,
				 <&gcc GCC_SDCC1_ICE_CORE_CLK>;
			clock-names = "iface_clk", "core_clk", "ice_core_clk";
			qcom,ice-clk-rates = <160000000 308570000>;
			qcom,large-address-bus;
			qcom,disable-aggressive-pm;

			status = "disabled";
		};

		sdhc_2: sdhci_sd@7804000 {
			compatible = "qcom,sdhci-msm-v5";
			reg = <0x7804000 0x1000>;
			reg-names = "hc_mem";

			interrupts = <GIC_SPI 123 IRQ_TYPE_NONE>,
					<GIC_SPI 138 IRQ_TYPE_NONE>;
			interrupt-names = "hc_irq", "pwr_irq";

			qcom,bus-width = <4>;
			qcom,dedicated-io = <1>;
			/* device core power supply */
			qcom,vdd-voltage-level = <2950000 2950000>;
			qcom,vdd-current-level = <15000 400000>;

			/* device communication power supply */
			qcom,vdd-io-lpm-sup;
			qcom,vdd-io-voltage-level = <1800000 2950000>;
			qcom,vdd-io-current-level = <200 22000>;
			qcom,vdd-io-always-on;

			qcom,cpu-dma-latency-us = <701>;
			qcom,msm-bus,name = "sdhc2";
			qcom,msm-bus,num-cases = <8>;
			qcom,msm-bus,num-paths = <1>;
			qcom,msm-bus,vectors-KBps = <81 512 0 0>, /* No vote */
				<81 512 1046 3200>,    /* 400 KB/s*/
				<81 512 52286 160000>, /* 20 MB/s */
				<81 512 65360 200000>, /* 25 MB/s */
				<81 512 130718 400000>, /* 50 MB/s */
				<81 512 261438 800000>, /* 100 MB/s */
				<81 512 261438 800000>, /* 200 MB/s */
				<81 512 1338562 4096000>; /* Max. bandwidth */
			qcom,bus-bw-vectors-bps = <0 400000 20000000 25000000 \
						50000000 100000000 200000000 \
						4294967295>;

			clocks = <&gcc GCC_SDCC1_AHB_CLK>,
				 <&gcc GCC_SDCC1_APPS_CLK>;
			clock-names = "iface_clk", "core_clk";
			qcom,large-address-bus;
			qcom,disable-aggressive-pm;

			status = "disabled";
		};

		edma@3ab00000 {
			compatible = "qcom,edma";
			reg = <0x3ab00000 0xabe00>;
			reg-names = "edma-reg-base";
			qcom,txdesc-ring-start = <23>;
			qcom,txdesc-rings = <1>;
			qcom,txcmpl-ring-start = <23>;
			qcom,txcmpl-rings = <1>;
			qcom,rxfill-ring-start = <7>;
			qcom,rxfill-rings = <1>;
			qcom,rxdesc-ring-start = <15>;
			qcom,rxdesc-rings = <1>;
			interrupts = <0 378 4>,
				   <0 354 4>,
				   <0 346 4>,
				   <0 379 4>;
			resets = <&gcc GCC_EDMA_HW_RESET>;
			reset-names = "edma_rst";
		};

		nss-common {
			compatible = "qcom,nss-common";
			reg = <0x01868010 0x1000>, <0x40000000 0x1000>;
			reg-names = "nss-misc-reset", "nss-misc-reset-flag";
		};

		nss0: nss@40000000 {
			compatible = "qcom,nss";
			interrupts = <0 402 0x1>, <0 401 0x1>, <0 400 0x1>,
				     <0 399 0x1>, <0 398 0x1>, <0 397 0x1>,
				     <0 396 0x1>, <0 395 0x1>, <0 394 0x1>;
			reg = <0x39000000 0x1000>, <0x0b111000 0x1000>;
			reg-names = "nphys", "qgic-phys";
			clocks = <&gcc GCC_NSS_NOC_CLK>,
				 <&gcc GCC_NSS_PTP_REF_CLK>,
				 <&gcc GCC_NSS_CSR_CLK>, <&gcc GCC_NSS_CFG_CLK>,
				 <&gcc GCC_NSSNOC_QOSGEN_REF_CLK>,
				 <&gcc GCC_NSSNOC_SNOC_CLK>,
				 <&gcc GCC_NSSNOC_TIMEOUT_REF_CLK>,
				 <&gcc GCC_NSS_CE_AXI_CLK>,
				 <&gcc GCC_NSS_CE_APB_CLK>,
				 <&gcc GCC_NSSNOC_CE_AXI_CLK>,
				 <&gcc GCC_NSSNOC_CE_APB_CLK>,
				 <&gcc GCC_NSSNOC_UBI0_AHB_CLK>,
				 <&gcc GCC_UBI0_CORE_CLK>,
				 <&gcc GCC_UBI0_AHB_CLK>,
				 <&gcc GCC_UBI0_AXI_CLK>,
				 <&gcc GCC_UBI0_NC_AXI_CLK>;
			clock-names = "nss-noc-clk", "nss-ptp-ref-clk",
				      "nss-csr-clk", "nss-cfg-clk",
				      "nss-nssnoc-qosgen-ref-clk",
				      "nss-nssnoc-snoc-clk",
				      "nss-nssnoc-timeout-ref-clk",
				      "nss-ce-axi-clk", "nss-ce-apb-clk",
				      "nss-nssnoc-ce-axi-clk",
				      "nss-nssnoc-ce-apb-clk",
				      "nss-nssnoc-ahb-clk",
				      "nss-core-clk", "nss-ahb-clk",
				      "nss-axi-clk", "nss-nc-axi-clk";
			qcom,id = <0>;
			qcom,num-queue = <4>;
			qcom,num-irq = <9>;
			qcom,num-pri = <4>;
			qcom,load-addr = <0x40000000>;
			qcom,low-frequency = <748800000>;
			qcom,mid-frequency = <1497600000>;
			qcom,max-frequency = <1497600000>;
			qcom,bridge-enabled;
			qcom,ipv4-enabled;
			qcom,ipv4-reasm-enabled;
			qcom,ipv6-enabled;
			qcom,ipv6-reasm-enabled;
			qcom,wlanredirect-enabled;
			qcom,tun6rd-enabled;
			qcom,l2tpv2-enabled;
			qcom,gre-enabled;
			qcom,gre-redir-enabled;
			qcom,map-t-enabled;
			qcom,portid-enabled;
			qcom,ppe-enabled;
			qcom,pppoe-enabled;
			qcom,pptp-enabled;
			qcom,tunipip6-enabled;
			qcom,shaping-enabled;
			qcom,wlan-dataplane-offload-enabled;
			qcom,vlan-enabled;
			qcom,capwap-enabled;
			qcom,dtls-enabled;
			qcom,crypto-enabled;
			qcom,ipsec-enabled;
		};

		nss_crypto: qcom,nss_crypto {
			compatible = "qcom,nss-crypto";
			qcom,max-contexts = <64>;
			qcom,max-context-size = <32>;
			ranges;

			eip197_node {
				compatible = "qcom,eip197";
				reg-names = "crypto_pbase";
				reg = <0x39800000 0x7ffff>;
				clocks = <&gcc GCC_NSS_CRYPTO_CLK>,
					<&gcc GCC_NSSNOC_CRYPTO_CLK>,
					<&gcc GCC_CRYPTO_PPE_CLK>;
				clock-names = "crypto_clk", "crypto_nocclk",
						"crypto_ppeclk";
				clock-frequency = /bits/ 64 <600000000 600000000 300000000>;
				qcom,dma-mask = <0xff>;
				qcom,transform-enabled;
				qcom,aes128-cbc;
				qcom,aes192-cbc;
				qcom,aes256-cbc;
				qcom,aes128-ctr;
				qcom,aes192-ctr;
				qcom,aes256-ctr;
				qcom,aes128-ecb;
				qcom,aes192-ecb;
				qcom,aes256-ecb;
				qcom,3des-cbc;
				qcom,md5-hash;
				qcom,sha160-hash;
				qcom,sha224-hash;
				qcom,sha256-hash;
				qcom,sha384-hash;
				qcom,sha512-hash;
				qcom,md5-hmac;
				qcom,sha160-hmac;
				qcom,sha256-hmac;
				qcom,sha384-hmac;
				qcom,sha512-hmac;
				qcom,aes128-gcm-gmac;
				qcom,aes192-gcm-gmac;
				qcom,aes256-gcm-gmac;
				qcom,aes128-cbc-md5-hmac;
				qcom,aes128-cbc-sha160-hmac;
				qcom,aes192-cbc-md5-hmac;
				qcom,aes192-cbc-sha160-hmac;
				qcom,aes256-cbc-md5-hmac;
				qcom,aes256-cbc-sha160-hmac;
				qcom,aes128-ctr-sha160-hmac;
				qcom,aes192-ctr-sha160-hmac;
				qcom,aes256-ctr-sha160-hmac;
				qcom,aes128-ctr-md5-hmac;
				qcom,aes192-ctr-md5-hmac;
				qcom,aes256-ctr-md5-hmac;
				qcom,3des-cbc-md5-hmac;
				qcom,3des-cbc-sha160-hmac;
				qcom,aes128-cbc-sha256-hmac;
				qcom,aes192-cbc-sha256-hmac;
				qcom,aes256-cbc-sha256-hmac;
				qcom,aes128-ctr-sha256-hmac;
				qcom,aes192-ctr-sha256-hmac;
				qcom,aes256-ctr-sha256-hmac;
				qcom,3des-cbc-sha256-hmac;

				engine0 {
					reg_offset = <0x80000>;
					qcom,ifpp-enabled;
					qcom,ipue-enabled;
					qcom,ofpp-enabled;
					qcom,opue-enabled;
				};
			};
		};

		acc0:clock-controller@b188000 {
			compatible = "qcom,arm-cortex-acc";
			reg = <0x0b188000 0x1000>;
		};

		acc1:clock-controller@b198000 {
			compatible = "qcom,arm-cortex-acc";
			reg = <0x0b198000 0x1000>;
		};

		acc2:clock-controller@b1a8000 {
			compatible = "qcom,arm-cortex-acc";
			reg = <0x0b1a8000 0x1000>;
		};

		acc3:clock-controller@b1b8000 {
			compatible = "qcom,arm-cortex-acc";
			reg = <0x0b1b8000 0x1000>;
		};

		tlmm: pinctrl@1000000 {
			compatible = "qcom,ipq6018-pinctrl";
			reg = <0x1000000 0x300000>;
			interrupts = <GIC_SPI 0xd0 IRQ_TYPE_NONE>;
			gpio-controller;
			#gpio-cells = <0x2>;
			interrupt-controller;
			#interrupt-cells = <0x2>;
		};

		watchdog: watchdog@b017000 {
			compatible = "qcom,kpss-wdt-ipq6018";
			reg = <0xb017000 0x1000>;
			reg-names = "kpss_wdt";
			interrupt-names = "bark_irq";
			interrupts = <GIC_SPI 3 IRQ_TYPE_NONE>;
			clocks = <&sleep_clk>;
			timeout-sec = <30>;
			wdt-max-timeout = <32>;
		};

		ess-switch@3a000000 {
			compatible = "qcom,ess-switch-ipq60xx";
			reg = <0x3a000000 0x1000000>;
			switch_access_mode = "local bus";
			switch_cpu_bmp = <0x1>;  /* cpu port bitmap */
			switch_lan_bmp = <0x1e>; /* lan port bitmap */
			switch_wan_bmp = <0x20>; /* wan port bitmap */
			switch_inner_bmp = <0xc0>; /*inner port bitmap*/
			switch_mac_mode = <0x0>; /* mac mode for uniphy 0*/
			switch_mac_mode1 = <0xd>; /* mac mode for uniphy 1*/
			switch_mac_mode2 = <0xff>; /* mac mode for uniphy 2*/
			bm_tick_mode = <0>; /* bm tick mode */
			tm_tick_mode = <0>; /* tm tick mode */
			port_scheduler_resource {
				port@0 {
					port_id = <0>;
					ucast_queue = <0 143>;
					mcast_queue = <256 271>;
					l0sp = <0 35>;
					l0cdrr = <0 47>;
					l0edrr = <0 47>;
					l1cdrr = <0 7>;
					l1edrr = <0 7>;
				};
				port@1 {
					port_id = <1>;
					ucast_queue = <144 159>;
					mcast_queue = <272 275>;
					l0sp = <36 39>;
					l0cdrr = <48 63>;
					l0edrr = <48 63>;
					l1cdrr = <8 11>;
					l1edrr = <8 11>;
				};
				port@2 {
					port_id = <2>;
					ucast_queue = <160 175>;
					mcast_queue = <276 279>;
					l0sp = <40 43>;
					l0cdrr = <64 79>;
					l0edrr = <64 79>;
					l1cdrr = <12 15>;
					l1edrr = <12 15>;
				};
				port@3 {
					port_id = <3>;
					ucast_queue = <176 191>;
					mcast_queue = <280 283>;
					l0sp = <44 47>;
					l0cdrr = <80 95>;
					l0edrr = <80 95>;
					l1cdrr = <16 19>;
					l1edrr = <16 19>;
				};
				port@4 {
					port_id = <4>;
					ucast_queue = <192 207>;
					mcast_queue = <284 287>;
					l0sp = <48 51>;
					l0cdrr = <96 111>;
					l0edrr = <96 111>;
					l1cdrr = <20 23>;
					l1edrr = <20 23>;
				};
				port@5 {
					port_id = <5>;
					ucast_queue = <208 223>;
					mcast_queue = <288 291>;
					l0sp = <52 55>;
					l0cdrr = <112 127>;
					l0edrr = <112 127>;
					l1cdrr = <24 27>;
					l1edrr = <24 27>;
				};
				port@6 {
					port_id = <6>;
					ucast_queue = <224 239>;
					mcast_queue = <292 295>;
					l0sp = <56 59>;
					l0cdrr = <128 143>;
					l0edrr = <128 143>;
					l1cdrr = <28 31>;
					l1edrr = <28 31>;
				};
				port@7 {
					port_id = <7>;
					ucast_queue = <240 255>;
					mcast_queue = <296 299>;
					l0sp = <60 63>;
					l0cdrr = <144 159>;
					l0edrr = <144 159>;
					l1cdrr = <32 35>;
					l1edrr = <32 35>;
				};
			};
			port_scheduler_config {
				port@0 {
					port_id = <0>;
					l1scheduler {
						group@0 {
							sp = <0 1>; /*L0 SPs*/
							/*cpri cdrr epri edrr*/
							cfg = <0 0 0 0>;
						};
					};
					l0scheduler {
						group@0 {
							/*unicast queues*/
							ucast_queue = <0 4 8>;
							/*multicast queues*/
							mcast_queue = <256 260>;
							/*sp cpricdrrepriedrr*/
							cfg = <0 0 0 0 0>;
						};
						group@1 {
							ucast_queue = <1 5 9>;
							mcast_queue = <257 261>;
							cfg = <0 1 1 1 1>;
						};
						group@2 {
							ucast_queue = <2 6 10>;
							mcast_queue = <258 262>;
							cfg = <0 2 2 2 2>;
						};
						group@3 {
							ucast_queue = <3 7 11>;
							mcast_queue = <259 263>;
							cfg = <0 3 3 3 3>;
						};
					};
				};
				port@1 {
					port_id = <1>;
					l1scheduler {
						group@0 {
							sp = <36>;
							cfg = <0 8 0 8>;
						};
						group@1 {
							sp = <37>;
							cfg = <1 9 1 9>;
						};
					};
					l0scheduler {
						group@0 {
							ucast_queue = <144>;
							ucast_loop_pri = <16>;
							mcast_queue = <272>;
							mcast_loop_pri = <4>;
							cfg = <36 0 48 0 48>;
						};
					};
				};
				port@2 {
					port_id = <2>;
					l1scheduler {
						group@0 {
							sp = <40>;
							cfg = <0 12 0 12>;
						};
						group@1 {
							sp = <41>;
							cfg = <1 13 1 13>;
						};
					};
					l0scheduler {
						group@0 {
							ucast_queue = <160>;
							ucast_loop_pri = <16>;
							mcast_queue = <276>;
							mcast_loop_pri = <4>;
							cfg = <40 0 64 0 64>;
						};
					};
				};
				port@3 {
					port_id = <3>;
					l1scheduler {
						group@0 {
							sp = <44>;
							cfg = <0 16 0 16>;
						};
						group@1 {
							sp = <45>;
							cfg = <1 17 1 17>;
						};
					};
					l0scheduler {
						group@0 {
							ucast_queue = <176>;
							ucast_loop_pri = <16>;
							mcast_queue = <280>;
							mcast_loop_pri = <4>;
							cfg = <44 0 80 0 80>;
						};
					};
				};
				port@4 {
					port_id = <4>;
					l1scheduler {
						group@0 {
							sp = <48>;
							cfg = <0 20 0 20>;
						};
						group@1 {
							sp = <49>;
							cfg = <1 21 1 21>;
						};
					};
					l0scheduler {
						group@0 {
							ucast_queue = <192>;
							ucast_loop_pri = <16>;
							mcast_queue = <284>;
							mcast_loop_pri = <4>;
							cfg = <48 0 96 0 96>;
						};
					};
				};
				port@5 {
					port_id = <5>;
					l1scheduler {
						group@0 {
							sp = <52>;
							cfg = <0 24 0 24>;
						};
						group@1 {
							sp = <53>;
							cfg = <1 25 1 25>;
						};
					};
					l0scheduler {
						group@0 {
							ucast_queue = <208>;
							ucast_loop_pri = <16>;
							mcast_queue = <288>;
							mcast_loop_pri = <4>;
							cfg = <52 0 112 0 112>;
						};
					};
				};
				port@6 {
					port_id = <6>;
					l1scheduler {
						group@0 {
							sp = <56>;
							cfg = <0 28 0 28>;
						};
						group@1 {
							sp = <57>;
							cfg = <1 29 1 29>;
						};
					};
					l0scheduler {
						group@0 {
							ucast_queue = <224>;
							ucast_loop_pri = <16>;
							mcast_queue = <292>;
							mcast_loop_pri = <4>;
							cfg = <56 0 128 0 128>;
						};
					};
				};
				port@7 {
					port_id = <7>;
					l1scheduler {
						group@0 {
							sp = <60>;
							cfg = <0 32 0 32>;
						};
						group@1 {
							sp = <61>;
							cfg = <1 33 1 33>;
						};
					};
					l0scheduler {
						group@0 {
							ucast_queue = <240>;
							ucast_loop_pri = <16>;
							mcast_queue = <296>;
							cfg = <60 0 144 0 144>;
						};
					};
				};
			};
		};

		wifi0: wifi@c000000 {
			compatible = "qcom,cnss-qca6018";
			reg = <0xc000000 0x1000000>;
			qcom,hw-mode-id = <1>;
		#ifdef __IPQ_MEM_PROFILE_256_MB__
			qcom,tgt-mem-mode = <2>;
		#elif __IPQ_MEM_PROFILE_512_MB__
			qcom,tgt-mem-mode = <1>;
		#else
			qcom,tgt-mem-mode = <0>;
		#endif
			qcom,bdf-addr = <0x4B900000 0x4B900000 0x4B900000>;
			qcom,caldb-addr = <0x4B940000 0x4B940000 0x4B940000>;
			interrupts = <0 320 1>, /* o_wcss_apps_intr[0] =  */
			<0 319 1>,
			<0 318 1>,
			<0 317 1>,
			<0 316 1>,
			<0 315 1>,
			<0 314 1>,
			<0 311 1>,
			<0 310 1>,
			<0 411 1>,
			<0 410 1>,
			<0 40 1>,
			<0 39 1>,
			<0 302 1>,
			<0 301 1>,
			<0 37 1>,
			<0 36 1>,
			<0 296 1>,
			<0 295 1>,
			<0 294 1>,
			<0 293 1>,
			<0 292 1>,
			<0 291 1>,
			<0 290 1>,
			<0 289 1>,
			<0 288 1>, /* o_wcss_apps_intr[25] */

			<0 239 1>,
			<0 236 1>,
			<0 235 1>,
			<0 234 1>,
			<0 233 1>,
			<0 232 1>,
			<0 231 1>,
			<0 230 1>,
			<0 229 1>,
			<0 228 1>,
			<0 224 1>,
			<0 223 1>,

			<0 203 1>,

			<0 183 1>,
			<0 180 1>,
			<0 179 1>,
			<0 178 1>,
			<0 177 1>,
			<0 176 1>,

			<0 163 1>,
			<0 162 1>,
			<0 160 1>,
			<0 159 1>,
			<0 158 1>,
			<0 157 1>,
			<0 156 1>; /* o_wcss_apps_intr[51] */

			interrupt-names = "misc-pulse1",
			"misc-latch",
			"sw-exception",
			"watchdog",
			"ce0",
			"ce1",
			"ce2",
			"ce3",
			"ce4",
			"ce5",
			"ce6",
			"ce7",
			"ce8",
			"ce9",
			"ce10",
			"ce11",
			"host2wbm-desc-feed",
			"host2reo-re-injection",
			"host2reo-command",
			"host2rxdma-monitor-ring3",
			"host2rxdma-monitor-ring2",
			"host2rxdma-monitor-ring1",
			"reo2ost-exception",
			"wbm2host-rx-release",
			"reo2host-status",
			"reo2host-destination-ring4",
			"reo2host-destination-ring3",
			"reo2host-destination-ring2",
			"reo2host-destination-ring1",
			"rxdma2host-monitor-destination-mac3",
			"rxdma2host-monitor-destination-mac2",
			"rxdma2host-monitor-destination-mac1",
			"ppdu-end-interrupts-mac3",
			"ppdu-end-interrupts-mac2",
			"ppdu-end-interrupts-mac1",
			"rxdma2host-monitor-status-ring-mac3",
			"rxdma2host-monitor-status-ring-mac2",
			"rxdma2host-monitor-status-ring-mac1",
			"host2rxdma-host-buf-ring-mac3",
			"host2rxdma-host-buf-ring-mac2",
			"host2rxdma-host-buf-ring-mac1",
			"rxdma2host-destination-ring-mac3",
			"rxdma2host-destination-ring-mac2",
			"rxdma2host-destination-ring-mac1",
			"host2tcl-input-ring4",
			"host2tcl-input-ring3",
			"host2tcl-input-ring2",
			"host2tcl-input-ring1",
			"wbm2host-tx-completions-ring3",
			"wbm2host-tx-completions-ring2",
			"wbm2host-tx-completions-ring1",
			"tcl2host-status-ring";
			status = "ok";
		};

		smmu500: arm,smmu@1E00000 {
			compatible = "arm,smmu-v2";
			reg = <0x01E00000 0x40000>;
			#iommu-cells = <1>;
			#global-interrupts = <1>;
			interrupts = <GIC_SPI 41 IRQ_TYPE_LEVEL_HIGH>,
				     <GIC_SPI 70 IRQ_TYPE_LEVEL_HIGH>,
				     <GIC_SPI 71 IRQ_TYPE_LEVEL_HIGH>,
				     <GIC_SPI 73 IRQ_TYPE_LEVEL_HIGH>,
				     <GIC_SPI 240 IRQ_TYPE_LEVEL_HIGH>,
				     <GIC_SPI 241 IRQ_TYPE_LEVEL_HIGH>,
				     <GIC_SPI 242 IRQ_TYPE_LEVEL_HIGH>,
				     <GIC_SPI 245 IRQ_TYPE_LEVEL_HIGH>,
				     <GIC_SPI 246 IRQ_TYPE_LEVEL_HIGH>,
				     <GIC_SPI 247 IRQ_TYPE_LEVEL_HIGH>,
				     <GIC_SPI 248 IRQ_TYPE_LEVEL_HIGH>,
				     <GIC_SPI 249 IRQ_TYPE_LEVEL_HIGH>,
				     <GIC_SPI 250 IRQ_TYPE_LEVEL_HIGH>,
				     <GIC_SPI 251 IRQ_TYPE_LEVEL_HIGH>,
				     <GIC_SPI 252 IRQ_TYPE_LEVEL_HIGH>,
				     <GIC_SPI 253 IRQ_TYPE_LEVEL_HIGH>,
				     <GIC_SPI 254 IRQ_TYPE_LEVEL_HIGH>,
				     <GIC_SPI 255 IRQ_TYPE_LEVEL_HIGH>,
				     <GIC_SPI 53 IRQ_TYPE_LEVEL_HIGH>,
				     <GIC_SPI 54 IRQ_TYPE_LEVEL_HIGH>,
				     <GIC_SPI 58 IRQ_TYPE_LEVEL_HIGH>,
				     <GIC_SPI 60 IRQ_TYPE_LEVEL_HIGH>,
				     <GIC_SPI 61 IRQ_TYPE_LEVEL_HIGH>,
				     <GIC_SPI 76 IRQ_TYPE_LEVEL_HIGH>,
				     <GIC_SPI 77 IRQ_TYPE_LEVEL_HIGH>,
				     <GIC_SPI 80 IRQ_TYPE_LEVEL_HIGH>,
				     <GIC_SPI 94 IRQ_TYPE_LEVEL_HIGH>,
				     <GIC_SPI 101 IRQ_TYPE_LEVEL_HIGH>,
				     <GIC_SPI 102 IRQ_TYPE_LEVEL_HIGH>,
				     <GIC_SPI 103 IRQ_TYPE_LEVEL_HIGH>,
				     <GIC_SPI 104 IRQ_TYPE_LEVEL_HIGH>,
				     <GIC_SPI 105 IRQ_TYPE_LEVEL_HIGH>,
				     <GIC_SPI 106 IRQ_TYPE_LEVEL_HIGH>;
			status = "disabled";
		};

		msm_imem: qcom,msm-imem@8600000 {
			compatible = "qcom,msm-imem";
			reg = <0x08600000 0x1000>;
			ranges = <0x0 0x08600000 0x1000>;
			#address-cells = <1>;
			#size-cells = <1>;

			mem_dump_table@10 {
				compatible = "qcom,msm-imem-mem_dump_table";
				reg = <0x10 8>;
			};
		};

		qca,scm_restart_reason {
			compatible = "qca,scm_restart_reason";
		};
	};

	psci {
		compatible = "arm,psci-1.0";
		method = "smc";
		status = "ok";
	};

	cpus {
		#address-cells = <0x1>;
		#size-cells = <0x0>;

		CPU0: cpu@0 {
			device_type = "cpu";
			compatible = "arm,cortex-a53", "arm,armv8";
			reg = <0x0>;
			enable-method = "psci";
			qcom,acc = <&acc0>;
			next-level-cache = <&L2_0>;

			L2_0: l2-cache {
				compatible = "cache";
				cache-level = <0x2>;
			};
		};

		CPU1: cpu@1 {
			device_type = "cpu";
			compatible = "arm,cortex-a53", "arm,armv8";
			enable-method = "psci";
			qcom,acc = <&acc1>;
			reg = <0x1>;
			next-level-cache = <&L2_0>;
		};

		CPU2: cpu@2 {
			device_type = "cpu";
			compatible = "arm,cortex-a53", "arm,armv8";
			enable-method = "psci";
			qcom,acc = <&acc2>;
			reg = <0x2>;
			next-level-cache = <&L2_0>;
		};

		CPU3: cpu@3 {
			device_type = "cpu";
			compatible = "arm,cortex-a53", "arm,armv8";
			enable-method = "psci";
			qcom,acc = <&acc3>;
			reg = <0x3>;
			next-level-cache = <&L2_0>;
		};
	};

	firmware {
		scm {
			compatible = "qcom,scm-ipq6018";
		};
		qfprom {
			compatible = "qcom,qfprom-sec";
		};
	};

	pmu {
		compatible = "arm,armv8-pmuv3";
		interrupts = <GIC_PPI 7 (GIC_CPU_MASK_SIMPLE(4) |
					 IRQ_TYPE_LEVEL_HIGH)>;
	};

	clocks {
		sleep_clk: sleep_clk {
			compatible = "fixed-clock";
			clock-frequency = <32000>;
			#clock-cells = <0>;
		};

		xo: xo {
			compatible = "fixed-clock";
			clock-frequency = <24000000>;
			#clock-cells = <0>;
		};
	};

	ion_dummy {
		compatible = "ipq60xx-ion-dummy";
		status = "disabled";
	};
};

#include "qcom-ipq6018-coresight.dtsi"
